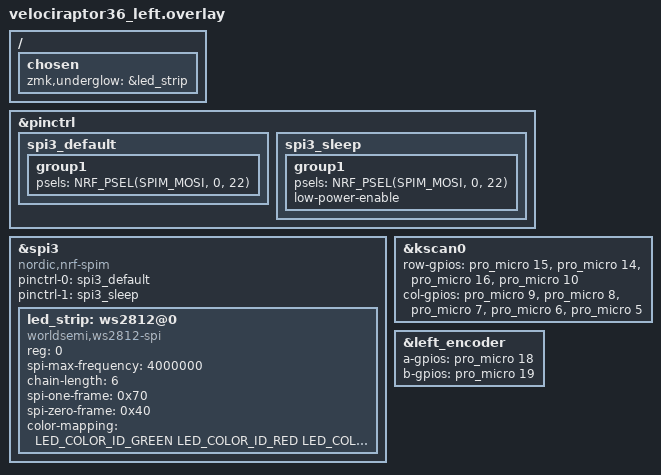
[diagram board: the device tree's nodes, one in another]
/*
 * Copyright (c) 2026
 *
 * SPDX-License-Identifier: MIT
 */

#include "velociraptor36.dtsi"
#include <dt-bindings/led/led.h>

&pinctrl {
    spi3_default: spi3_default {
        group1 {
            psels = <NRF_PSEL(SPIM_MOSI, 0, 22)>;
        };
    };

    spi3_sleep: spi3_sleep {
        group1 {
            psels = <NRF_PSEL(SPIM_MOSI, 0, 22)>;
            low-power-enable;
        };
    };
};

&spi3 {
    compatible = "nordic,nrf-spim";
    status = "okay";

    pinctrl-0 = <&spi3_default>;
    pinctrl-1 = <&spi3_sleep>;
    pinctrl-names = "default", "sleep";

    led_strip: ws2812@0 {
        compatible = "worldsemi,ws2812-spi";

        reg = <0>;
        spi-max-frequency = <4000000>;

        chain-length = <6>;
        spi-one-frame = <0x70>;
        spi-zero-frame = <0x40>;

        color-mapping = <LED_COLOR_ID_GREEN LED_COLOR_ID_RED LED_COLOR_ID_BLUE>;
    };
};

/ {
    chosen {
        zmk,underglow = &led_strip;
    };
};

&kscan0 {
    /* Rows top-to-bottom: P1.13, P1.11, P0.10, P0.09 */
    row-gpios
        = <&pro_micro 15 (GPIO_ACTIVE_HIGH | GPIO_PULL_DOWN)>
        , <&pro_micro 14 (GPIO_ACTIVE_HIGH | GPIO_PULL_DOWN)>
        , <&pro_micro 16 (GPIO_ACTIVE_HIGH | GPIO_PULL_DOWN)>
        , <&pro_micro 10 (GPIO_ACTIVE_HIGH | GPIO_PULL_DOWN)>
        ;

    /* Cols: P1.06, P1.04, P0.11, P1.00, P0.24 */
    col-gpios
        = <&pro_micro 9 GPIO_ACTIVE_HIGH>
        , <&pro_micro 8 GPIO_ACTIVE_HIGH>
        , <&pro_micro 7 GPIO_ACTIVE_HIGH>
        , <&pro_micro 6 GPIO_ACTIVE_HIGH>
        , <&pro_micro 5 GPIO_ACTIVE_HIGH>
        ;
};

&left_encoder {
    status = "okay";
    /* Swap A/B if only one direction works after flashing. */
    a-gpios = <&pro_micro 18 (GPIO_ACTIVE_HIGH | GPIO_PULL_UP)>;
    b-gpios = <&pro_micro 19 (GPIO_ACTIVE_HIGH | GPIO_PULL_UP)>;
};
